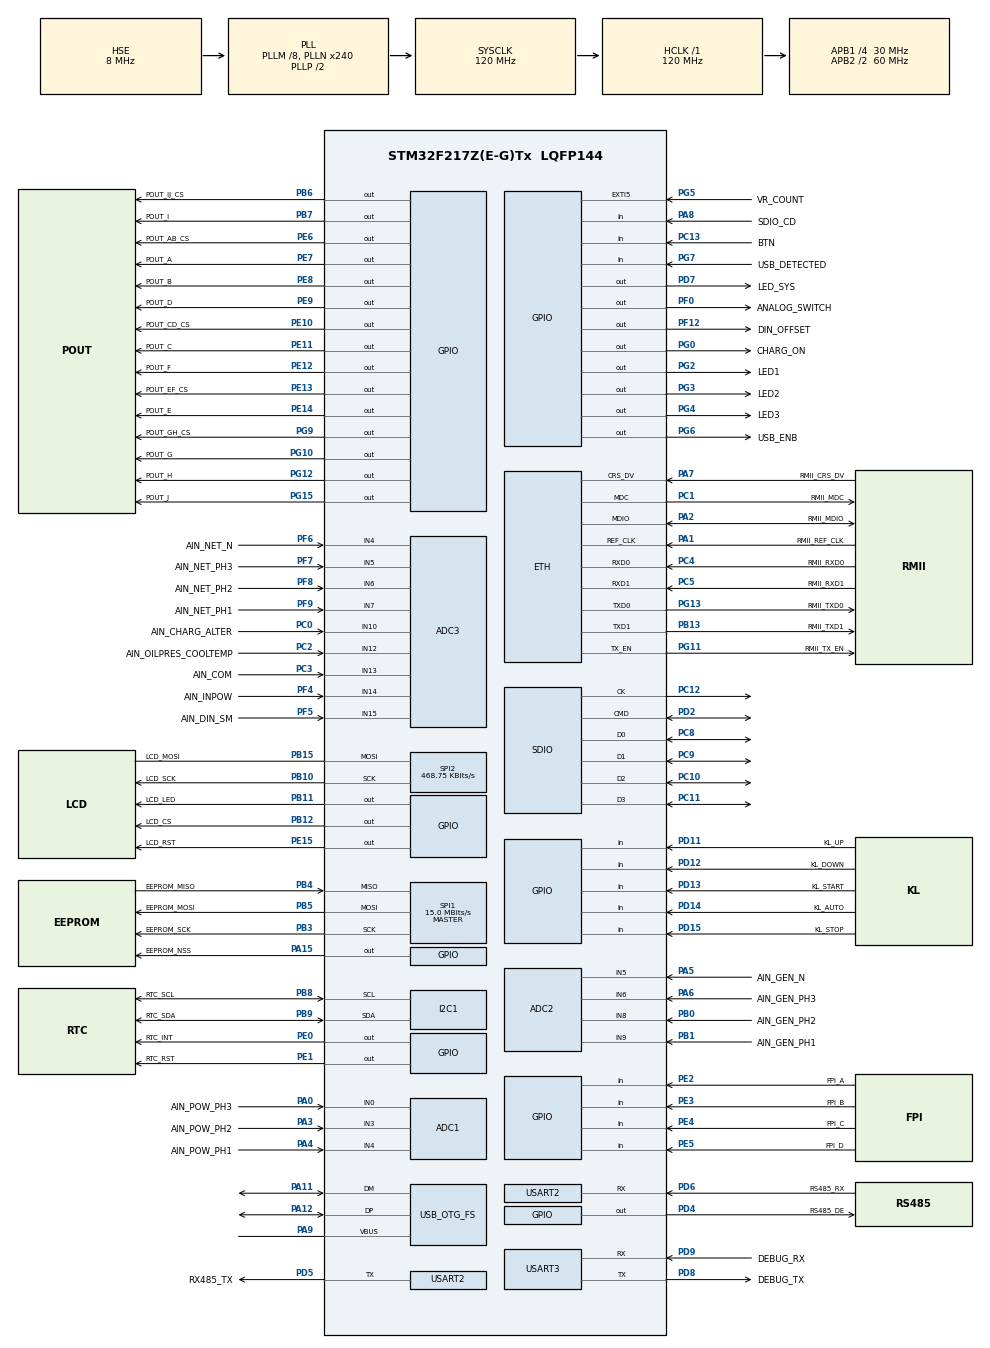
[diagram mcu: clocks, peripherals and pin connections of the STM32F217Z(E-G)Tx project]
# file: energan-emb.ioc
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ADC1.Channel-0\#ChannelRegularConversion=ADC_CHANNEL_0
ADC1.Channel-1\#ChannelRegularConversion=ADC_CHANNEL_3
ADC1.Channel-2\#ChannelRegularConversion=ADC_CHANNEL_4
ADC1.ClockPrescaler=ADC_CLOCK_SYNC_PCLK_DIV2
ADC1.DMAContinuousRequests=ENABLE
ADC1.ExternalTrigConv=ADC_EXTERNALTRIGCONV_T2_TRGO
ADC1.NbrOfConversion=3
ADC1.NbrOfConversionFlag=1
ADC1.Rank-0\#ChannelRegularConversion=1
ADC1.Rank-1\#ChannelRegularConversion=2
ADC1.Rank-2\#ChannelRegularConversion=3
ADC1.SamplingTime-0\#ChannelRegularConversion=ADC_SAMPLETIME_112CYCLES
ADC1.SamplingTime-1\#ChannelRegularConversion=ADC_SAMPLETIME_112CYCLES
ADC1.SamplingTime-2\#ChannelRegularConversion=ADC_SAMPLETIME_112CYCLES
ADC1.ScanConvMode=ENABLE
ADC1.master=1
ADC2.Channel-1\#ChannelRegularConversion=ADC_CHANNEL_6
ADC2.Channel-2\#ChannelRegularConversion=ADC_CHANNEL_8
ADC2.Channel-3\#ChannelRegularConversion=ADC_CHANNEL_9
ADC2.Channel-4\#ChannelRegularConversion=ADC_CHANNEL_5
ADC2.DMAContinuousRequests=ENABLE
ADC2.ExternalTrigConv=ADC_EXTERNALTRIGCONV_T8_TRGO
ADC2.NbrOfConversion=4
ADC2.NbrOfConversionFlag=1
ADC2.Rank-1\#ChannelRegularConversion=1
ADC2.Rank-2\#ChannelRegularConversion=2
ADC2.Rank-3\#ChannelRegularConversion=3
ADC2.Rank-4\#ChannelRegularConversion=4
ADC2.SamplingTime-1\#ChannelRegularConversion=ADC_SAMPLETIME_112CYCLES
ADC2.SamplingTime-2\#ChannelRegularConversion=ADC_SAMPLETIME_112CYCLES
ADC2.SamplingTime-3\#ChannelRegularConversion=ADC_SAMPLETIME_112CYCLES
ADC2.SamplingTime-4\#ChannelRegularConversion=ADC_SAMPLETIME_112CYCLES
ADC2.ScanConvMode=ENABLE
ADC3.Channel-0\#ChannelRegularConversion=ADC_CHANNEL_5
ADC3.Channel-10\#ChannelRegularConversion=ADC_CHANNEL_13
ADC3.Channel-11\#ChannelRegularConversion=ADC_CHANNEL_12
ADC3.Channel-12\#ChannelRegularConversion=ADC_CHANNEL_10
ADC3.Channel-5\#ChannelRegularConversion=ADC_CHANNEL_6
ADC3.Channel-6\#ChannelRegularConversion=ADC_CHANNEL_7
ADC3.Channel-7\#ChannelRegularConversion=ADC_CHANNEL_4
ADC3.Channel-8\#ChannelRegularConversion=ADC_CHANNEL_14
ADC3.Channel-9\#ChannelRegularConversion=ADC_CHANNEL_15
ADC3.DMAContinuousRequests=ENABLE
ADC3.ExternalTrigConv=ADC_EXTERNALTRIGCONV_T3_TRGO
ADC3.InjNumberOfConversion=0
ADC3.NbrOfConversion=9
ADC3.NbrOfConversionFlag=1
ADC3.Rank-0\#ChannelRegularConversion=1
ADC3.Rank-10\#ChannelRegularConversion=7
ADC3.Rank-11\#ChannelRegularConversion=8
ADC3.Rank-12\#ChannelRegularConversion=9
ADC3.Rank-5\#ChannelRegularConversion=2
ADC3.Rank-6\#ChannelRegularConversion=3
ADC3.Rank-7\#ChannelRegularConversion=4
ADC3.Rank-8\#ChannelRegularConversion=5
ADC3.Rank-9\#ChannelRegularConversion=6
ADC3.SamplingTime-0\#ChannelRegularConversion=ADC_SAMPLETIME_112CYCLES
ADC3.SamplingTime-10\#ChannelRegularConversion=ADC_SAMPLETIME_112CYCLES
ADC3.SamplingTime-11\#ChannelRegularConversion=ADC_SAMPLETIME_112CYCLES
ADC3.SamplingTime-12\#ChannelRegularConversion=ADC_SAMPLETIME_112CYCLES
ADC3.SamplingTime-5\#ChannelRegularConversion=ADC_SAMPLETIME_112CYCLES
ADC3.SamplingTime-6\#ChannelRegularConversion=ADC_SAMPLETIME_112CYCLES
ADC3.SamplingTime-7\#ChannelRegularConversion=ADC_SAMPLETIME_112CYCLES
ADC3.SamplingTime-8\#ChannelRegularConversion=ADC_SAMPLETIME_112CYCLES
ADC3.SamplingTime-9\#ChannelRegularConversion=ADC_SAMPLETIME_112CYCLES
ADC3.ScanConvMode=ENABLE
Dma.ADC1.2.Direction=DMA_PERIPH_TO_MEMORY
Dma.ADC1.2.FIFOMode=DMA_FIFOMODE_DISABLE
Dma.ADC1.2.Instance=DMA2_Stream0
Dma.ADC1.2.MemDataAlignment=DMA_MDATAALIGN_HALFWORD
Dma.ADC1.2.MemInc=DMA_MINC_ENABLE
Dma.ADC1.2.Mode=DMA_NORMAL
Dma.ADC1.2.PeriphDataAlignment=DMA_PDATAALIGN_HALFWORD
Dma.ADC1.2.PeriphInc=DMA_PINC_DISABLE
Dma.ADC1.2.Priority=DMA_PRIORITY_LOW
Dma.ADC2.1.Direction=DMA_PERIPH_TO_MEMORY
Dma.ADC2.1.FIFOMode=DMA_FIFOMODE_DISABLE
Dma.ADC2.1.Instance=DMA2_Stream2
Dma.ADC2.1.MemDataAlignment=DMA_MDATAALIGN_HALFWORD
Dma.ADC2.1.MemInc=DMA_MINC_ENABLE
Dma.ADC2.1.Mode=DMA_NORMAL
Dma.ADC2.1.PeriphDataAlignment=DMA_PDATAALIGN_HALFWORD
Dma.ADC2.1.PeriphInc=DMA_PINC_DISABLE
Dma.ADC2.1.Priority=DMA_PRIORITY_LOW
Dma.ADC3.0.Direction=DMA_PERIPH_TO_MEMORY
Dma.ADC3.0.FIFOMode=DMA_FIFOMODE_DISABLE
Dma.ADC3.0.Instance=DMA2_Stream1
Dma.ADC3.0.MemDataAlignment=DMA_MDATAALIGN_HALFWORD
Dma.ADC3.0.MemInc=DMA_MINC_ENABLE
Dma.ADC3.0.Mode=DMA_NORMAL
Dma.ADC3.0.PeriphDataAlignment=DMA_PDATAALIGN_HALFWORD
Dma.ADC3.0.PeriphInc=DMA_PINC_DISABLE
Dma.ADC3.0.Priority=DMA_PRIORITY_LOW
Dma.Request0=ADC3
Dma.Request1=ADC2
Dma.Request2=ADC1
Dma.Request3=SPI2_TX
Dma.Request4=SDIO_RX
Dma.Request5=SDIO_TX
Dma.SDIO_RX.4.Direction=DMA_PERIPH_TO_MEMORY
Dma.SDIO_RX.4.FIFOMode=DMA_FIFOMODE_ENABLE
Dma.SDIO_RX.4.FIFOThreshold=DMA_FIFO_THRESHOLD_FULL
Dma.SDIO_RX.4.Instance=DMA2_Stream3
Dma.SDIO_RX.4.MemBurst=DMA_MBURST_INC4
Dma.SDIO_RX.4.MemDataAlignment=DMA_MDATAALIGN_WORD
Dma.SDIO_RX.4.MemInc=DMA_MINC_ENABLE
Dma.SDIO_RX.4.Mode=DMA_PFCTRL
Dma.SDIO_RX.4.PeriphBurst=DMA_PBURST_INC4
Dma.SDIO_RX.4.PeriphDataAlignment=DMA_PDATAALIGN_WORD
Dma.SDIO_RX.4.PeriphInc=DMA_PINC_DISABLE
Dma.SDIO_RX.4.Priority=DMA_PRIORITY_LOW
Dma.SDIO_TX.5.Direction=DMA_MEMORY_TO_PERIPH
Dma.SDIO_TX.5.FIFOMode=DMA_FIFOMODE_ENABLE
Dma.SDIO_TX.5.FIFOThreshold=DMA_FIFO_THRESHOLD_FULL
Dma.SDIO_TX.5.Instance=DMA2_Stream6
Dma.SDIO_TX.5.MemBurst=DMA_MBURST_INC4
Dma.SDIO_TX.5.MemDataAlignment=DMA_MDATAALIGN_WORD
Dma.SDIO_TX.5.MemInc=DMA_MINC_ENABLE
Dma.SDIO_TX.5.Mode=DMA_PFCTRL
Dma.SDIO_TX.5.PeriphBurst=DMA_PBURST_INC4
Dma.SDIO_TX.5.PeriphDataAlignment=DMA_PDATAALIGN_WORD
Dma.SDIO_TX.5.PeriphInc=DMA_PINC_DISABLE
Dma.SDIO_TX.5.Priority=DMA_PRIORITY_LOW
Dma.SPI2_TX.3.Direction=DMA_MEMORY_TO_PERIPH
Dma.SPI2_TX.3.FIFOMode=DMA_FIFOMODE_DISABLE
Dma.SPI2_TX.3.Instance=DMA1_Stream4
Dma.SPI2_TX.3.MemDataAlignment=DMA_MDATAALIGN_BYTE
Dma.SPI2_TX.3.MemInc=DMA_MINC_ENABLE
Dma.SPI2_TX.3.Mode=DMA_NORMAL
Dma.SPI2_TX.3.PeriphDataAlignment=DMA_PDATAALIGN_BYTE
Dma.SPI2_TX.3.PeriphInc=DMA_PINC_DISABLE
Dma.SPI2_TX.3.Priority=DMA_PRIORITY_LOW
ETH.MACAddr=00\:10\:FA\:6E\:38\:4A
ETH.MediaInterface=ETH_MEDIA_INTERFACE_RMII
ETH.PHY_DUPLEX_STATUS=0x0010
ETH.PHY_SPEED_STATUS=0x0004
ETH.PHY_SR=0x1F
ETH.PhyAddress=0
FATFS.BSP.number=1
FATFS._CODE_PAGE=1
FATFS0.BSP.STBoard=false
FATFS0.BSP.api=Unknown
FATFS0.BSP.i2caddr=0
FATFS0.BSP.instance=PA8
FATFS0.BSP.ip=GPIO
FATFS0.BSP.mode=Input
FATFS0.BSP.name=Detect_SDIO
FATFS0.BSP.solution=PA8
FREERTOS.BinarySemaphores01=xLCDDelaySemph,Dynamic,NULL
FREERTOS.Tasks01=defaultTask,24,128,StartDefaultTask,Default,NULL,Dynamic,NULL,NULL;lcdTask,8,256,StartLcdTask,Default,NULL,Dynamic,NULL,NULL;usbTask,8,192,vStartUsbTask,As external,NULL,Dynamic,NULL,NULL;adcTask,24,403,StartADCTask,As external,NULL,Dynamic,NULL,NULL;keyboardTask,40,128,vKeyboardTask,As external,NULL,Dynamic,NULL,NULL;wdTask,32,128,vWDtask,Default,NULL,Dynamic,NULL,NULL
FREERTOS.configTIMER_TASK_PRIORITY=55
FREERTOS.configTOTAL_HEAP_SIZE=30720
IWDG.Prescaler=IWDG_PRESCALER_16
IWDG.Reload=3999
LWIP.CHECKSUM_BY_HARDWARE=0
LWIP.Version=v2.0.3_Cube
Mcu.Family=STM32F2
Mcu.Name=STM32F217Z(E-G)Tx
Mcu.Package=LQFP144
NVIC.DMA1_Stream4_IRQn=true\:5\:0\:false\:false\:true\:true\:false\:true\:true
NVIC.DMA2_Stream0_IRQn=true\:5\:0\:false\:false\:true\:true\:false\:true\:true
NVIC.DMA2_Stream1_IRQn=true\:5\:0\:false\:false\:true\:true\:false\:true\:true
NVIC.DMA2_Stream2_IRQn=true\:5\:0\:false\:false\:true\:true\:false\:true\:true
NVIC.DMA2_Stream3_IRQn=true\:5\:0\:false\:false\:true\:true\:false\:true\:true
NVIC.DMA2_Stream6_IRQn=true\:5\:0\:false\:false\:true\:true\:false\:true\:true
NVIC.ETH_IRQn=true\:5\:0\:false\:false\:true\:true\:false\:true\:true
NVIC.EXTI9_5_IRQn=true\:5\:0\:false\:false\:true\:true\:true\:true\:true
NVIC.OTG_FS_IRQn=true\:5\:0\:false\:false\:true\:true\:false\:true\:true
NVIC.PriorityGroup=NVIC_PRIORITYGROUP_4
NVIC.SDIO_IRQn=true\:5\:0\:false\:false\:true\:true\:true\:true\:true
NVIC.TIM2_IRQn=true\:5\:0\:false\:false\:true\:true\:true\:true\:true
NVIC.TIM3_IRQn=true\:5\:0\:false\:false\:true\:true\:true\:true\:true
NVIC.TIM4_IRQn=true\:0\:0\:false\:false\:true\:false\:false\:true\:true
NVIC.TIM5_IRQn=true\:5\:0\:false\:false\:true\:true\:true\:true\:true
NVIC.TIM6_DAC_IRQn=true\:5\:0\:false\:false\:true\:true\:true\:true\:true
NVIC.TIM7_IRQn=true\:5\:0\:false\:false\:true\:true\:true\:true\:true
NVIC.TIM8_BRK_TIM12_IRQn=true\:5\:0\:false\:false\:true\:true\:true\:true\:true
NVIC.TIM8_UP_TIM13_IRQn=true\:5\:0\:false\:false\:true\:true\:true\:true\:true
NVIC.TimeBase=TIM4_IRQn
NVIC.TimeBaseIP=TIM4
NVIC.USART2_IRQn=true\:5\:0\:false\:false\:true\:true\:true\:true\:true
NVIC.USART3_IRQn=true\:5\:0\:false\:false\:true\:true\:true\:true\:true
PA0-WKUP.GPIO_Label=AIN_POW_PH3
PA0-WKUP.Signal=ADCx_IN0
PA1.GPIO_Label=RMII_REF_CLK
PA1.Mode=RMII
PA1.Signal=ETH_REF_CLK
PA11.Mode=Device_Only
PA11.Signal=USB_OTG_FS_DM
PA12.Mode=Device_Only
PA12.Signal=USB_OTG_FS_DP
PA13.GPIO_Label=SWDIO
PA13.Mode=Serial_Wire
PA13.Signal=SYS_JTMS-SWDIO
PA14.GPIO_Label=SWCLK
PA14.Mode=Serial_Wire
PA14.Signal=SYS_JTCK-SWCLK
PA15.GPIO_Label=EEPROM_NSS
PA15.Signal=GPIO_Output
PA2.GPIO_Label=RMII_MDIO
PA2.Mode=RMII
PA2.Signal=ETH_MDIO
PA3.GPIO_Label=AIN_POW_PH2
PA3.Signal=ADCx_IN3
PA4.GPIO_Label=AIN_POW_PH1
PA4.Signal=ADCx_IN4
PA5.GPIO_Label=AIN_GEN_N
PA5.Signal=ADCx_IN5
PA6.GPIO_Label=AIN_GEN_PH3
PA6.Signal=ADCx_IN6
PA7.GPIO_Label=RMII_CRS_DV
PA7.Mode=RMII
PA7.Signal=ETH_CRS_DV
PA8.GPIO_Label=SDIO_CD
PA8.Signal=GPIO_Input
PA9.Mode=Activate_VBUS
PA9.Signal=USB_OTG_FS_VBUS
PB0.GPIO_Label=AIN_GEN_PH2
PB0.Signal=ADCx_IN8
PB1.GPIO_Label=AIN_GEN_PH1
PB1.Signal=ADCx_IN9
PB10.GPIO_Label=LCD_SCK
PB10.Mode=Simplex_Bidirectional_Master
PB10.Signal=SPI2_SCK
PB11.GPIO_Label=LCD_LED
PB11.Signal=GPIO_Output
PB12.GPIO_Label=LCD_CS
PB12.Signal=GPIO_Output
PB13.GPIO_Label=RMII_TXD1
PB13.Mode=RMII
PB13.Signal=ETH_TXD1
PB14.GPIO_Label=LCD_MISO
PB14.Signal=SPI2_MISO
PB15.GPIO_Label=LCD_MOSI
PB15.Mode=Simplex_Bidirectional_Master
PB15.Signal=SPI2_MOSI
PB3.GPIO_Label=EEPROM_SCK
PB3.Mode=Full_Duplex_Master
PB3.Signal=SPI1_SCK
PB4.GPIO_Label=EEPROM_MISO
PB4.Mode=Full_Duplex_Master
PB4.Signal=SPI1_MISO
PB5.GPIO_Label=EEPROM_MOSI
PB5.Mode=Full_Duplex_Master
PB5.Signal=SPI1_MOSI
PB6.GPIO_Label=POUT_IJ_CS
PB6.Signal=GPIO_Output
PB7.GPIO_Label=POUT_I
PB7.Signal=GPIO_Output
PB8.GPIO_Label=RTC_SCL
PB8.GPIO_Pu=GPIO_PULLUP
PB8.Mode=I2C
PB8.Signal=I2C1_SCL
PB9.GPIO_Label=RTC_SDA
PB9.GPIO_Pu=GPIO_PULLUP
PB9.Mode=I2C
PB9.Signal=I2C1_SDA
PC0.GPIO_Label=AIN_CHARG_ALTER
PC0.Signal=ADCx_IN10
PC1.GPIO_Label=RMII_MDC
PC1.Mode=RMII
PC1.Signal=ETH_MDC
PC10.Mode=SD_4_bits_Wide_bus
PC10.Signal=SDIO_D2
PC11.Mode=SD_4_bits_Wide_bus
PC11.Signal=SDIO_D3
PC12.Mode=SD_4_bits_Wide_bus
PC12.Signal=SDIO_CK
PC13.GPIO_Label=BTN
PC13.Signal=GPIO_Input
PC14-OSC32_IN.Signal=RCC_OSC32_IN
PC2.GPIO_Label=AIN_OILPRES_COOLTEMP
PC2.Signal=ADCx_IN12
PC3.GPIO_Label=AIN_COM
PC3.Signal=ADCx_IN13
PC4.GPIO_Label=RMII_RXD0
PC4.Mode=RMII
PC4.Signal=ETH_RXD0
PC5.GPIO_Label=RMII_RXD1
PC5.Mode=RMII
PC5.Signal=ETH_RXD1
PC8.Mode=SD_4_bits_Wide_bus
PC8.Signal=SDIO_D0
PC9.Mode=SD_4_bits_Wide_bus
PC9.Signal=SDIO_D1
PD0.Signal=CAN1_RX
PD1.Signal=CAN1_TX
PD11.GPIO_Label=KL_UP
PD11.Signal=GPIO_Input
PD12.GPIO_Label=KL_DOWN
PD12.Signal=GPIO_Input
PD13.GPIO_Label=KL_START
PD13.Signal=GPIO_Input
PD14.GPIO_Label=KL_AUTO
PD14.Signal=GPIO_Input
PD15.GPIO_Label=KL_STOP
PD15.Signal=GPIO_Input
PD2.Mode=SD_4_bits_Wide_bus
PD2.Signal=SDIO_CMD
PD4.GPIO_Label=RS485_DE
PD4.Signal=GPIO_Output
PD5.GPIO_Label=RX485_TX
PD5.Mode=Asynchronous
PD5.Signal=USART2_TX
PD6.GPIO_Label=RS485_RX
PD6.Mode=Asynchronous
PD6.Signal=USART2_RX
PD7.GPIO_Label=LED_SYS
PD7.PinState=GPIO_PIN_SET
PD7.Signal=GPIO_Output
PD8.GPIO_Label=DEBUG_TX
PD8.Mode=Asynchronous
PD8.Signal=USART3_TX
PD9.GPIO_Label=DEBUG_RX
PD9.Mode=Asynchronous
PD9.Signal=USART3_RX
PE0.GPIO_Label=RTC_INT
PE0.Signal=GPIO_Output
PE1.GPIO_Label=RTC_RST
PE1.Signal=GPIO_Output
PE10.GPIO_Label=POUT_CD_CS
PE10.Signal=GPIO_Output
PE11.GPIO_Label=POUT_C
PE11.Signal=GPIO_Output
PE12.GPIO_Label=POUT_F
PE12.Signal=GPIO_Output
PE13.GPIO_Label=POUT_EF_CS
PE13.Signal=GPIO_Output
PE14.GPIO_Label=POUT_E
PE14.Signal=GPIO_Output
PE15.GPIO_Label=LCD_RST
PE15.PinState=GPIO_PIN_SET
PE15.Signal=GPIO_Output
PE2.GPIO_Label=FPI_A
PE2.Signal=GPIO_Input
PE3.GPIO_Label=FPI_B
PE3.Signal=GPIO_Input
PE4.GPIO_Label=FPI_C
PE4.Signal=GPIO_Input
PE5.GPIO_Label=FPI_D
PE5.Signal=GPIO_Input
PE6.GPIO_Label=POUT_AB_CS
PE6.Signal=GPIO_Output
PE7.GPIO_Label=POUT_A
PE7.Signal=GPIO_Output
PE8.GPIO_Label=POUT_B
PE8.Signal=GPIO_Output
PE9.GPIO_Label=POUT_D
PE9.Signal=GPIO_Output
PF0.GPIO_Label=ANALOG_SWITCH
PF0.Signal=GPIO_Output
PF10.Signal=ADC3_IN8
PF12.GPIO_Label=DIN_OFFSET
PF12.Signal=GPIO_Output
PF4.GPIO_Label=AIN_INPOW
PF4.Mode=IN14
PF4.Signal=ADC3_IN14
PF5.GPIO_Label=AIN_DIN_SM
PF5.Mode=IN15
PF5.Signal=ADC3_IN15
PF6.GPIO_Label=AIN_NET_N
PF6.Mode=IN4
PF6.Signal=ADC3_IN4
PF7.GPIO_Label=AIN_NET_PH3
PF7.Mode=IN5
PF7.Signal=ADC3_IN5
PF8.GPIO_Label=AIN_NET_PH2
PF8.Mode=IN6
PF8.Signal=ADC3_IN6
PF9.GPIO_Label=AIN_NET_PH1
PF9.Mode=IN7
PF9.Signal=ADC3_IN7
PG0.GPIO_Label=CHARG_ON
PG0.Signal=GPIO_Output
PG10.GPIO_Label=POUT_G
PG10.Signal=GPIO_Output
PG11.GPIO_Label=RMII_TX_EN
PG11.Mode=RMII
PG11.Signal=ETH_TX_EN
PG12.GPIO_Label=POUT_H
PG12.Signal=GPIO_Output
PG13.GPIO_Label=RMII_TXD0
PG13.Mode=RMII
PG13.Signal=ETH_TXD0
PG15.GPIO_Label=POUT_J
PG15.Signal=GPIO_Output
PG2.GPIO_Label=LED1
PG2.PinState=GPIO_PIN_SET
PG2.Signal=GPIO_Output
PG3.GPIO_Label=LED2
PG3.PinState=GPIO_PIN_SET
PG3.Signal=GPIO_Output
PG4.GPIO_Label=LED3
PG4.PinState=GPIO_PIN_SET
PG4.Signal=GPIO_Output
PG5.GPIO_Label=VR_COUNT
PG5.Signal=GPXTI5
PG6.GPIO_Label=USB_ENB
PG6.Signal=GPIO_Output
PG7.GPIO_Label=USB_DETECTED
PG7.Signal=GPIO_Input
PG9.GPIO_Label=POUT_GH_CS
PG9.Signal=GPIO_Output
PH0-OSC_IN.Mode=HSE-External-Oscillator
PH0-OSC_IN.Signal=RCC_OSC_IN
PH1-OSC_OUT.Mode=HSE-External-Oscillator
PH1-OSC_OUT.Signal=RCC_OSC_OUT
ProjectManager.HeapSize=0x200
ProjectManager.StackSize=0x400
ProjectManager.TargetToolchain=STM32CubeIDE
RCC.48MHZClocksFreq_Value=48000000
RCC.AHBFreq_Value=120000000
RCC.APB1CLKDivider=RCC_HCLK_DIV4
RCC.APB1Freq_Value=30000000
RCC.APB1TimFreq_Value=60000000
RCC.APB2CLKDivider=RCC_HCLK_DIV2
RCC.APB2Freq_Value=60000000
RCC.APB2TimFreq_Value=120000000
RCC.CortexFreq_Value=120000000
RCC.HCLKFreq_Value=120000000
RCC.HSE_VALUE=8000000
RCC.HSI_VALUE=16000000
RCC.LSE_VALUE=32768
RCC.PLLM=8
RCC.PLLN=240
RCC.PLLQ=5
RCC.PLLSourceVirtual=RCC_PLLSOURCE_HSE
RCC.SYSCLKFreq_VALUE=120000000
RCC.SYSCLKSource=RCC_SYSCLKSOURCE_PLLCLK
RCC.VCOOutputFreq_Value=240000000
SDIO.ClockDiv=6
SH.ADCx_IN0.0=ADC1_IN0,IN0
SH.ADCx_IN10.0=ADC3_IN10,IN10
SH.ADCx_IN12.0=ADC3_IN12,IN12
SH.ADCx_IN13.0=ADC3_IN13,IN13
SH.ADCx_IN3.0=ADC1_IN3,IN3
SH.ADCx_IN4.0=ADC1_IN4,IN4
SH.ADCx_IN5.0=ADC2_IN5,IN5
SH.ADCx_IN6.0=ADC2_IN6,IN6
SH.ADCx_IN8.0=ADC2_IN8,IN8
SH.ADCx_IN9.0=ADC2_IN9,IN9
SPI1.BaudRatePrescaler=SPI_BAUDRATEPRESCALER_4
SPI1.CalculateBaudRate=15.0 MBits/s
SPI1.Direction=SPI_DIRECTION_2LINES
SPI1.Mode=SPI_MODE_MASTER
SPI1.VirtualType=VM_MASTER
SPI2.BaudRatePrescaler=SPI_BAUDRATEPRESCALER_64
SPI2.CLKPhase=SPI_PHASE_2EDGE
SPI2.CLKPolarity=SPI_POLARITY_HIGH
SPI2.CalculateBaudRate=468.75 KBits/s
SPI2.Direction=SPI_DIRECTION_1LINE
SPI2.Mode=SPI_MODE_MASTER
SPI2.VirtualType=VM_MASTER
TIM12.Period=201
TIM12.Prescaler=30001
TIM2.ClockDivision=TIM_CLOCKDIVISION_DIV4
TIM2.Period=1000
TIM2.TIM_MasterOutputTrigger=TIM_TRGO_UPDATE
TIM2.TIM_MasterSlaveMode=TIM_MASTERSLAVEMODE_DISABLE
TIM3.AutoReloadPreload=TIM_AUTORELOAD_PRELOAD_ENABLE
TIM3.ClockDivision=TIM_CLOCKDIVISION_DIV4
TIM3.Period=1000
TIM3.TIM_MasterOutputTrigger=TIM_TRGO_UPDATE
TIM5.Period=201
TIM5.Prescaler=30001
TIM6.Period=2001
TIM6.Prescaler=30001
TIM7.Period=72
TIM7.Prescaler=60
TIM8.AutoReloadPreload=TIM_AUTORELOAD_PRELOAD_ENABLE
TIM8.ClockDivision=TIM_CLOCKDIVISION_DIV4
TIM8.Period=1000
TIM8.TIM_MasterOutputTrigger=TIM_TRGO_UPDATE
TIM8.TIM_MasterSlaveMode=TIM_MASTERSLAVEMODE_DISABLE
USART2.VirtualMode=VM_ASYNC
USART3.VirtualMode=VM_ASYNC
USB_DEVICE.CLASS_NAME_FS=CUSTOM_HID
USB_DEVICE.CONFIGURATION_STRING_CUSTOMHID_FS=Energan
USB_DEVICE.INTERFACE_STRING_CUSTOMHID_FS=Energan IO Interface
USB_DEVICE.MANUFACTURER_STRING-CUSTOM_HID_FS=Energan
USB_DEVICE.PID_CUSTOMHID_FS=4285
USB_DEVICE.PRODUCT_STRING_CUSTOMHID_FS=Enrgan Diesel Generator Controller 
USB_DEVICE.USBD_CUSTOMHID_OUTREPORT_BUF_SIZE-CUSTOM_HID_FS=64
USB_DEVICE.USBD_CUSTOM_HID_REPORT_DESC_SIZE-CUSTOM_HID_FS=38
USB_DEVICE.VID-CUSTOM_HID_FS=5840
USB_DEVICE.VirtualMode-CUSTOM_HID_FS=CustomHid
USB_DEVICE.VirtualModeFS=Custom_Hid_FS
USB_OTG_FS.VirtualMode=Device_Only
VP_FATFS_VS_SDIO.Mode=SDIO
VP_FREERTOS_VS_CMSIS_V2.Mode=CMSIS_V2
VP_IWDG_VS_IWDG.Mode=IWDG_Activate
VP_LWIP_VS_Enabled.Mode=Enabled
VP_SYS_VS_tim4.Mode=TIM4
VP_TIM11_VS_ClockSourceINT.Mode=Enable_Timer
VP_TIM12_VS_ClockSourceINT.Mode=Internal
VP_TIM13_VS_ClockSourceINT.Mode=Enable_Timer
VP_TIM2_VS_ClockSourceINT.Mode=Internal
VP_TIM3_VS_ClockSourceINT.Mode=Internal
VP_TIM5_VS_ClockSourceINT.Mode=Internal
VP_TIM6_VS_ClockSourceINT.Mode=Enable_Timer
VP_TIM7_VS_ClockSourceINT.Mode=Enable_Timer
VP_TIM8_VS_ClockSourceINT.Mode=Internal
VP_USB_DEVICE_VS_USB_DEVICE_CUSTOM_HID_FS.Mode=CUSTOM_HID_FS
board=custom

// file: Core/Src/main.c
/* USER CODE BEGIN Header */
/**
  ******************************************************************************
  * @file           : main.c
  * @brief          : Main program body
  ******************************************************************************
  * @attention
  *
  * <h2><center>&copy; Copyright (c) 2021 STMicroelectronics.
  * All rights reserved.</center></h2>
  *
  * This software component is licensed by ST under BSD 3-Clause license,
  * the "License"; You may not use this file except in compliance with the
  * License. You may obtain a copy of the License at:
  *                        opensource.org/licenses/BSD-3-Clause
  *
  ******************************************************************************
  */
/* USER CODE END Header */
#include "main.h"
#include "cmsis_os.h"
#include "fatfs.h"
#include "lwip.h"
#include "usb_device.h"

/* USER CODE BEGIN Includes */
#include "task.h"
#include "EEPROM.h"
#include "RTC.h"
#include "common.h"
#include "chart.h"
#include "dataAPI.h"
#include "lcd.h"
#include "keyboard.h"
#include "menu.h"
#include "server.h"
#include "config.h"
#include "version.h"
#include "usbhid.h"
#include "storage.h"
#include "freeData.h"
#include "adc.h"
#include "fpi.h"
#include "fpo.h"
#include "vrSensor.h"
#include "engine.h"
#include "electro.h"
#include "controller.h"
#include "alarm.h"
#include "measurement.h"
#include "charger.h"
#include "mb.h"
#include "outputData.h"
#include "system.h"
#include "fatsd.h"

#include "dataSD.h"

#if defined ( UNIT_TEST )
  #include "unity.h"
  #include "tests.h"
#endif
/* USER CODE END Includes */

ADC_HandleTypeDef hadc1;
ADC_HandleTypeDef hadc2;
ADC_HandleTypeDef hadc3;
DMA_HandleTypeDef hdma_adc1;
DMA_HandleTypeDef hdma_adc2;
DMA_HandleTypeDef hdma_adc3;

I2C_HandleTypeDef hi2c1;

IWDG_HandleTypeDef hiwdg;

SD_HandleTypeDef hsd;
DMA_HandleTypeDef hdma_sdio_rx;
DMA_HandleTypeDef hdma_sdio_tx;

SPI_HandleTypeDef hspi1;
SPI_HandleTypeDef hspi2;
DMA_HandleTypeDef hdma_spi2_tx;

TIM_HandleTypeDef htim2;
TIM_HandleTypeDef htim3;
TIM_HandleTypeDef htim5;
TIM_HandleTypeDef htim6;
TIM_HandleTypeDef htim7;
TIM_HandleTypeDef htim8;
TIM_HandleTypeDef htim11;
TIM_HandleTypeDef htim12;
TIM_HandleTypeDef htim13;

UART_HandleTypeDef huart2;
UART_HandleTypeDef huart3;

/* Definitions for defaultTask */
osThreadId_t defaultTaskHandle;
const osThreadAttr_t defaultTask_attributes = {
  .name = "defaultTask",
  .stack_size = 128 * 4,
  .priority = (osPriority_t) osPriorityNormal,
};
/* Definitions for lcdTask */
osThreadId_t lcdTaskHandle;
const osThreadAttr_t lcdTask_attributes = {
  .name = "lcdTask",
  .stack_size = 256 * 4,
  .priority = (osPriority_t) osPriorityLow,
};
/* Definitions for usbTask */
osThreadId_t usbTaskHandle;
const osThreadAttr_t usbTask_attributes = {
  .name = "usbTask",
  .stack_size = 192 * 4,
  .priority = (osPriority_t) osPriorityLow,
};
/* Definitions for adcTask */
osThreadId_t adcTaskHandle;
const osThreadAttr_t adcTask_attributes = {
  .name = "adcTask",
  .stack_size = 403 * 4,
  .priority = (osPriority_t) osPriorityNormal,
};
/* Definitions for keyboardTask */
osThreadId_t keyboardTaskHandle;
const osThreadAttr_t keyboardTask_attributes = {
  .name = "keyboardTask",
  .stack_size = 128 * 4,
  .priority = (osPriority_t) osPriorityHigh,
};
/* Definitions for wdTask */
osThreadId_t wdTaskHandle;
const osThreadAttr_t wdTask_attributes = {
  .name = "wdTask",
  .stack_size = 128 * 4,
  .priority = (osPriority_t) osPriorityAboveNormal,
};
/* Definitions for xLCDDelaySemph */
osSemaphoreId_t xLCDDelaySemphHandle;
const osSemaphoreAttr_t xLCDDelaySemph_attributes = {
  .name = "xLCDDelaySemph"
};

void SystemClock_Config(void);
static void MX_GPIO_Init(void);
static void MX_DMA_Init(void);
static void MX_ADC3_Init(void);
static void MX_I2C1_Init(void);
static void MX_SPI1_Init(void);
static void MX_USART2_UART_Init(void);
static void MX_USART3_UART_Init(void);
static void MX_SPI2_Init(void);
static void MX_TIM2_Init(void);
static void MX_TIM3_Init(void);
static void MX_TIM5_Init(void);
static void MX_TIM6_Init(void);
static void MX_TIM7_Init(void);
static void MX_TIM11_Init(void);
static void MX_TIM12_Init(void);
static void MX_TIM13_Init(void);
static void MX_ADC2_Init(void);
static void MX_ADC1_Init(void);
static void MX_TIM8_Init(void);
static void MX_IWDG_Init(void);
static void MX_SDIO_SD_Init(void);
void StartDefaultTask(void *argument);
void StartLcdTask(void *argument);
extern void vStartUsbTask(void *argument);
extern void StartADCTask(void *argument);
extern void vKeyboardTask(void *argument);
void vWDtask(void *argument);

/* USER CODE BEGIN PFP */
/*
static const TaskHandle_t* notifyTrg[NOTIFY_TARGETS_NUMBER] =
{
  ( TaskHandle_t* )&lcdTaskHandle,
  ( TaskHandle_t* )&engineHandle,
  ( TaskHandle_t* )&fpiHandle,
  ( TaskHandle_t* )&controllerHandle,
  ( TaskHandle_t* )&electroHandle,
};
*/
static const FPI_INIT fpiInitStruct = {
  .pinA   = FPI_A_Pin,
  .pinB   = FPI_B_Pin,
  .pinC   = FPI_C_Pin,
  .pinD   = FPI_D_Pin,
  .pinCS  = DIN_OFFSET_Pin,
  .portA  = FPI_A_GPIO_Port,
  .portB  = FPI_B_GPIO_Port,
  .portC  = FPI_C_GPIO_Port,
  .portD  = FPI_D_GPIO_Port,
  .portCS = DIN_OFFSET_GPIO_Port
};
static const FPO_INIT fpoInitStruct = {
  .outPinA   = POUT_A_Pin,
  .outPinB   = POUT_B_Pin,
  .outPinC   = POUT_C_Pin,
  .outPinD   = POUT_D_Pin,
  .outPinE   = POUT_E_Pin,
  .outPinF   = POUT_F_Pin,
  .outPinG   = POUT_G_Pin,
  .outPinH   = POUT_H_Pin,
  .outPinI   = POUT_I_Pin,
  .outPinJ   = POUT_J_Pin,

  .outPortA  = POUT_A_GPIO_Port,
  .outPortB  = POUT_B_GPIO_Port,
  .outPortC  = POUT_C_GPIO_Port,
  .outPortD  = POUT_D_GPIO_Port,
  .outPortE  = POUT_E_GPIO_Port,
  .outPortF  = POUT_F_GPIO_Port,
  .outPortG  = POUT_G_GPIO_Port,
  .outPortH  = POUT_H_GPIO_Port,
  .outPortI  = POUT_I_GPIO_Port,
  .outPortJ  = POUT_J_GPIO_Port,

  .disPinAB  = POUT_AB_CS_Pin,
  .disPinCD  = POUT_CD_CS_Pin,
  .disPinEF  = POUT_EF_CS_Pin,
  .disPinGH  = POUT_GH_CS_Pin,
  .disPinIJ  = POUT_IJ_CS_Pin,
  .disPortAB = POUT_AB_CS_GPIO_Port,
  .disPortCD = POUT_CD_CS_GPIO_Port,
  .disPortEF = POUT_EF_CS_GPIO_Port,
  .disPortGH = POUT_GH_CS_GPIO_Port,
  .disPortIJ = POUT_IJ_CS_GPIO_Port,
};
static const CONTROLLER_INIT controllerInitStruct = {
  .autoPIN    = LED2_Pin,
  .autoGPIO   = LED2_GPIO_Port,
  .manualPIN  = 0U,
  .manualGPIO = NULL,
  .startPIN   = LED3_Pin,
  .startGPIO  = LED3_GPIO_Port,
  .loadPIN    = 0U,
  .loadGPIO   = NULL,
  .stopPIN    = LED1_Pin,
  .stopGPIO   = LED1_GPIO_Port,
};
static const MB_INIT_TYPE mbInit = {
  .uart = &huart2,
  .tim  = &htim13,
  .port = RS485_DE_GPIO_Port,
  .pin  = RS485_DE_Pin,
};
static const GPIO_TYPE chargGPIO = {
  .pin = CHARG_ON_Pin,
  .port = CHARG_ON_GPIO_Port,
};
static const EEPROM_TYPE storEE = {
  .SRWD      = M95Mxx_SRWD,
  .ID        = M95Mxx_ID,
  .protect   = M95Mxx_PROTECTION,
  .size      = M95M01_SIZE,
  .page      = M95Mxx_PAGE_SIZE,
  .frequensy = M95Mxx_CLOCK_FREQ,
  .timeout   = M95Mxx_TIMEOUT,
  .adrSize   = M95Mxx_ADR_SIZE,
  .spi       = &hspi1,
  .cs.pin    = EEPROM_NSS_Pin,
  .cs.port   = EEPROM_NSS_GPIO_Port
};
static const EEPROM_TYPE macEE = {
  .SRWD      = AA02E48_SRWD,
  .ID        = AA02E48_ID,
  .protect   = AA02E48_PROTECTION,
  .size      = AA02E48_SIZE,
  .page      = AA02E48_PAGE_SIZE,
  .frequensy = AA02E48_CLOCK_FREQ,
  .timeout   = AA02E48_TIMEOUT,
  .adrSize   = AA02E48_ADR_SIZE,
  .spi       = &hspi1,
  .cs.pin    = MAC_NSS_Pin,
  .cs.port   = MAC_NSS_GPIO_Port
};

/* USER CODE END PFP */

int main(void)
{

  /* MCU Configuration--------------------------------------------------------*/

  /* Reset of all peripherals, Initializes the Flash interface and the Systick. */

  HAL_Init();

  /* Configure the system clock */
  SystemClock_Config();

  /* Initialize all configured peripherals */
  MX_GPIO_Init();
  MX_DMA_Init();
  MX_ADC3_Init();
  MX_I2C1_Init();
  MX_SPI1_Init();
  MX_USART2_UART_Init();
  MX_USART3_UART_Init();
  MX_SPI2_Init();
  MX_TIM2_Init();
  MX_TIM3_Init();
  MX_TIM5_Init();
  MX_TIM6_Init();
  MX_TIM7_Init();
  MX_TIM11_Init();
  MX_TIM12_Init();
  MX_TIM13_Init();
  MX_ADC2_Init();
  MX_ADC1_Init();
  MX_TIM8_Init();
  MX_IWDG_Init();
  MX_SDIO_SD_Init();
  //MX_FATFS_Init();

  /* Init scheduler */
  osKernelInitialize();

  /* Create the semaphores(s) */
  /* creation of xLCDDelaySemph */
  xLCDDelaySemphHandle = osSemaphoreNew(1, 1, &xLCDDelaySemph_attributes);

  /* USER CODE BEGIN RTOS_SEMAPHORES */
  xLCDDelaySemphHandle = osSemaphoreNew(1, 1, &xLCDDelaySemph_attributes);
  /* USER CODE END RTOS_SEMAPHORES */

  /* Create the thread(s) */
  /* creation of defaultTask */
  defaultTaskHandle = osThreadNew(StartDefaultTask, NULL, &defaultTask_attributes);

  /* creation of lcdTask */
  lcdTaskHandle = osThreadNew(StartLcdTask, NULL, &lcdTask_attributes);

  /* creation of usbTask */
  usbTaskHandle = osThreadNew(vStartUsbTask, NULL, &usbTask_attributes);

  /* creation of adcTask */
  adcTaskHandle = osThreadNew(StartADCTask, NULL, &adcTask_attributes);

  /* creation of keyboardTask */
  keyboardTaskHandle = osThreadNew(vKeyboardTask, NULL, &keyboardTask_attributes);

  /* creation of wdTask */
  wdTaskHandle = osThreadNew(vWDtask, NULL, &wdTask_attributes);

  /* USER CODE BEGIN RTOS_EVENTS */
  vSetupKeyboard();
  vMenuMessageInit( adcTaskHandle );
  HAL_GPIO_WritePin( LCD_RST_GPIO_Port, LCD_RST_Pin, GPIO_PIN_SET );
  vLCDInit( xLCDDelaySemphHandle, &htim7, &hspi2 );
  vCHARTinitCharts();                               /* Charts data initialization */
  vRTCinit( &hi2c1 );                               /* RTC initialization         */
  vDATAAPIinit( &storEE );                          /* Data API initialization    */
  vUSBinit( usbTaskHandle );
  /* USER CODE END RTOS_EVENTS */

  /* Start scheduler */
  osKernelStart();

  /* We should never get here as control is now taken by the scheduler */
  /* Infinite loop */
  while (1)
  {

  }
}

void SystemClock_Config(void)
{
  RCC_OscInitTypeDef RCC_OscInitStruct = {0};
  RCC_ClkInitTypeDef RCC_ClkInitStruct = {0};

  /** Initializes the RCC Oscillators according to the specified parameters
  * in the RCC_OscInitTypeDef structure.
  */
  RCC_OscInitStruct.OscillatorType = RCC_OSCILLATORTYPE_LSI|RCC_OSCILLATORTYPE_HSE;
  RCC_OscInitStruct.HSEState = RCC_HSE_ON;
  RCC_OscInitStruct.LSIState = RCC_LSI_ON;
  RCC_OscInitStruct.PLL.PLLState = RCC_PLL_ON;
  RCC_OscInitStruct.PLL.PLLSource = RCC_PLLSOURCE_HSE;
  RCC_OscInitStruct.PLL.PLLM = 8;
  RCC_OscInitStruct.PLL.PLLN = 240;
  RCC_OscInitStruct.PLL.PLLP = RCC_PLLP_DIV2;
  RCC_OscInitStruct.PLL.PLLQ = 5;
  if (HAL_RCC_OscConfig(&RCC_OscInitStruct) != HAL_OK)
  {
    Error_Handler();
  }

  /** Initializes the CPU, AHB and APB buses clocks
  */
  RCC_ClkInitStruct.ClockType = RCC_CLOCKTYPE_HCLK|RCC_CLOCKTYPE_SYSCLK
                              |RCC_CLOCKTYPE_PCLK1|RCC_CLOCKTYPE_PCLK2;
  RCC_ClkInitStruct.SYSCLKSource = RCC_SYSCLKSOURCE_PLLCLK;
  RCC_ClkInitStruct.AHBCLKDivider = RCC_SYSCLK_DIV1;
  RCC_ClkInitStruct.APB1CLKDivider = RCC_HCLK_DIV4;
  RCC_ClkInitStruct.APB2CLKDivider = RCC_HCLK_DIV2;

  if (HAL_RCC_ClockConfig(&RCC_ClkInitStruct, FLASH_LATENCY_3) != HAL_OK)
  {
    Error_Handler();
  }
}

static void MX_ADC1_Init(void)
{

  ADC_ChannelConfTypeDef sConfig = {0};

  /** Configure the global features of the ADC (Clock, Resolution, Data Alignment and number of conversion)
  */
  hadc1.Instance = ADC1;
  hadc1.Init.ClockPrescaler = ADC_CLOCK_SYNC_PCLK_DIV2;
  hadc1.Init.Resolution = ADC_RESOLUTION_12B;
  hadc1.Init.ScanConvMode = ENABLE;
  hadc1.Init.ContinuousConvMode = DISABLE;
  hadc1.Init.DiscontinuousConvMode = DISABLE;
  hadc1.Init.ExternalTrigConvEdge = ADC_EXTERNALTRIGCONVEDGE_RISING;
  hadc1.Init.ExternalTrigConv = ADC_EXTERNALTRIGCONV_T2_TRGO;
  hadc1.Init.DataAlign = ADC_DATAALIGN_RIGHT;
  hadc1.Init.NbrOfConversion = 3;
  hadc1.Init.DMAContinuousRequests = ENABLE;
  hadc1.Init.EOCSelection = ADC_EOC_SINGLE_CONV;
  if (HAL_ADC_Init(&hadc1) != HAL_OK)
  {
    Error_Handler();
  }

  /** Configure for the selected ADC regular channel its corresponding rank in the sequencer and its sample time.
  */
  sConfig.Channel = ADC_CHANNEL_0;
  sConfig.Rank = 1;
  sConfig.SamplingTime = ADC_SAMPLETIME_112CYCLES;
  if (HAL_ADC_ConfigChannel(&hadc1, &sConfig) != HAL_OK)
  {
    Error_Handler();
  }

  /** Configure for the selected ADC regular channel its corresponding rank in the sequencer and its sample time.
  */
  sConfig.Channel = ADC_CHANNEL_3;
  sConfig.Rank = 2;
  if (HAL_ADC_ConfigChannel(&hadc1, &sConfig) != HAL_OK)
  {
    Error_Handler();
  }

  /** Configure for the selected ADC regular channel its corresponding rank in the sequencer and its sample time.
  */
  sConfig.Channel = ADC_CHANNEL_4;
  sConfig.Rank = 3;
  if (HAL_ADC_ConfigChannel(&hadc1, &sConfig) != HAL_OK)
  {
    Error_Handler();
  }
  /* USER CODE BEGIN ADC1_Init 2 */
  sConfig.Channel = ADC_CHANNEL_16;
  sConfig.Rank = 4;
  if (HAL_ADC_ConfigChannel(&hadc1, &sConfig) != HAL_OK)
  {
    Error_Handler();
  }
  /* USER CODE END ADC1_Init 2 */

}

static void MX_ADC2_Init(void)
{

  ADC_ChannelConfTypeDef sConfig = {0};

  /** Configure the global features of the ADC (Clock, Resolution, Data Alignment and number of conversion)
  */
  hadc2.Instance = ADC2;
  hadc2.Init.ClockPrescaler = ADC_CLOCK_SYNC_PCLK_DIV2;
  hadc2.Init.Resolution = ADC_RESOLUTION_12B;
  hadc2.Init.ScanConvMode = ENABLE;
  hadc2.Init.ContinuousConvMode = DISABLE;
  hadc2.Init.DiscontinuousConvMode = DISABLE;
  hadc2.Init.ExternalTrigConvEdge = ADC_EXTERNALTRIGCONVEDGE_RISING;
  hadc2.Init.ExternalTrigConv = ADC_EXTERNALTRIGCONV_T8_TRGO;
  hadc2.Init.DataAlign = ADC_DATAALIGN_RIGHT;
  hadc2.Init.NbrOfConversion = 4;
  hadc2.Init.DMAContinuousRequests = ENABLE;
  hadc2.Init.EOCSelection = ADC_EOC_SINGLE_CONV;
  if (HAL_ADC_Init(&hadc2) != HAL_OK)
  {
    Error_Handler();
  }

  /** Configure for the selected ADC regular channel its corresponding rank in the sequencer and its sample time.
  */
  sConfig.Channel = ADC_CHANNEL_6;
  sConfig.Rank = 1;
  sConfig.SamplingTime = ADC_SAMPLETIME_112CYCLES;
  if (HAL_ADC_ConfigChannel(&hadc2, &sConfig) != HAL_OK)
  {
    Error_Handler();
  }

  /** Configure for the selected ADC regular channel its corresponding rank in the sequencer and its sample time.
  */
  sConfig.Channel = ADC_CHANNEL_8;
  sConfig.Rank = 2;
  if (HAL_ADC_ConfigChannel(&hadc2, &sConfig) != HAL_OK)
  {
    Error_Handler();
  }

  /** Configure for the selected ADC regular channel its corresponding rank in the sequencer and its sample time.
  */
  sConfig.Channel = ADC_CHANNEL_9;
  sConfig.Rank = 3;
  if (HAL_ADC_ConfigChannel(&hadc2, &sConfig) != HAL_OK)
  {
    Error_Handler();
  }

  /** Configure for the selected ADC regular channel its corresponding rank in the sequencer and its sample time.
  */
  sConfig.Channel = ADC_CHANNEL_5;
  sConfig.Rank = 4;
  if (HAL_ADC_ConfigChannel(&hadc2, &sConfig) != HAL_OK)
  {
    Error_Handler();
  }

}

static void MX_ADC3_Init(void)
{

  ADC_ChannelConfTypeDef sConfig = {0};

  /** Configure the global features of the ADC (Clock, Resolution, Data Alignment and number of conversion)
  */
  hadc3.Instance = ADC3;
  hadc3.Init.ClockPrescaler = ADC_CLOCK_SYNC_PCLK_DIV2;
  hadc3.Init.Resolution = ADC_RESOLUTION_12B;
  hadc3.Init.ScanConvMode = ENABLE;
  hadc3.Init.ContinuousConvMode = DISABLE;
  hadc3.Init.DiscontinuousConvMode = DISABLE;
  hadc3.Init.ExternalTrigConvEdge = ADC_EXTERNALTRIGCONVEDGE_RISING;
  hadc3.Init.ExternalTrigConv = ADC_EXTERNALTRIGCONV_T3_TRGO;
  hadc3.Init.DataAlign = ADC_DATAALIGN_RIGHT;
  hadc3.Init.NbrOfConversion = 9;
  hadc3.Init.DMAContinuousRequests = ENABLE;
  hadc3.Init.EOCSelection = ADC_EOC_SINGLE_CONV;
  if (HAL_ADC_Init(&hadc3) != HAL_OK)
  {
    Error_Handler();
  }

  /** Configure for the selected ADC regular channel its corresponding rank in the sequencer and its sample time.
  */
  sConfig.Channel = ADC_CHANNEL_5;
  sConfig.Rank = 1;
  sConfig.SamplingTime = ADC_SAMPLETIME_112CYCLES;
  if (HAL_ADC_ConfigChannel(&hadc3, &sConfig) != HAL_OK)
  {
    Error_Handler();
  }

  /** Configure for the selected ADC regular channel its corresponding rank in the sequencer and its sample time.
  */
  sConfig.Channel = ADC_CHANNEL_6;
  sConfig.Rank = 2;
  if (HAL_ADC_ConfigChannel(&hadc3, &sConfig) != HAL_OK)
  {
    Error_Handler();
  }

  /** Configure for the selected ADC regular channel its corresponding rank in the sequencer and its sample time.
  */
  sConfig.Channel = ADC_CHANNEL_7;
  sConfig.Rank = 3;
  if (HAL_ADC_ConfigChannel(&hadc3, &sConfig) != HAL_OK)
  {
    Error_Handler();
  }

  /** Configure for the selected ADC regular channel its corresponding rank in the sequencer and its sample time.
  */
  sConfig.Channel = ADC_CHANNEL_4;
  sConfig.Rank = 4;
  if (HAL_ADC_ConfigChannel(&hadc3, &sConfig) != HAL_OK)
  {
    Error_Handler();
  }

  /** Configure for the selected ADC regular channel its corresponding rank in the sequencer and its sample time.
  */
  sConfig.Channel = ADC_CHANNEL_14;
  sConfig.Rank = 5;
  if (HAL_ADC_ConfigChannel(&hadc3, &sConfig) != HAL_OK)
  {
    Error_Handler();
  }

  /** Configure for the selected ADC regular channel its corresponding rank in the sequencer and its sample time.
  */
  sConfig.Channel = ADC_CHANNEL_15;
  sConfig.Rank = 6;
  if (HAL_ADC_ConfigChannel(&hadc3, &sConfig) != HAL_OK)
  {
    Error_Handler();
  }

  /** Configure for the selected ADC regular channel its corresponding rank in the sequencer and its sample time.
  */
  sConfig.Channel = ADC_CHANNEL_13;
  sConfig.Rank = 7;
  if (HAL_ADC_ConfigChannel(&hadc3, &sConfig) != HAL_OK)
  {
    Error_Handler();
  }

  /** Configure for the selected ADC regular channel its corresponding rank in the sequencer and its sample time.
  */
  sConfig.Channel = ADC_CHANNEL_12;
  sConfig.Rank = 8;
  if (HAL_ADC_ConfigChannel(&hadc3, &sConfig) != HAL_OK)
  {
    Error_Handler();
  }

  /** Configure for the selected ADC regular channel its corresponding rank in the sequencer and its sample time.
  */
  sConfig.Channel = ADC_CHANNEL_10;
  sConfig.Rank = 9;
  if (HAL_ADC_ConfigChannel(&hadc3, &sConfig) != HAL_OK)
  {
    Error_Handler();
  }

}

static void MX_I2C1_Init(void)
{

  hi2c1.Instance = I2C1;
  hi2c1.Init.ClockSpeed = 100000;
  hi2c1.Init.DutyCycle = I2C_DUTYCYCLE_2;
  hi2c1.Init.OwnAddress1 = 0;
  hi2c1.Init.AddressingMode = I2C_ADDRESSINGMODE_7BIT;
  hi2c1.Init.DualAddressMode = I2C_DUALADDRESS_DISABLE;
  hi2c1.Init.OwnAddress2 = 0;
  hi2c1.Init.GeneralCallMode = I2C_GENERALCALL_DISABLE;
  hi2c1.Init.NoStretchMode = I2C_NOSTRETCH_DISABLE;
  if (HAL_I2C_Init(&hi2c1) != HAL_OK)
  {
    Error_Handler();
  }

}

static void MX_IWDG_Init(void)
{

  /* USER CODE BEGIN IWDG_Init 0 */
  #ifdef DEBUG
    __HAL_DBGMCU_FREEZE_IWDG();
  #endif
  /* USER CODE END IWDG_Init 0 */

  hiwdg.Instance = IWDG;
  hiwdg.Init.Prescaler = IWDG_PRESCALER_16;
  hiwdg.Init.Reload = 3999;
  if (HAL_IWDG_Init(&hiwdg) != HAL_OK)
  {
    Error_Handler();
  }

}

static void MX_SDIO_SD_Init(void)
{

  hsd.Instance = SDIO;
  hsd.Init.ClockEdge = SDIO_CLOCK_EDGE_RISING;
  hsd.Init.ClockBypass = SDIO_CLOCK_BYPASS_DISABLE;
  hsd.Init.ClockPowerSave = SDIO_CLOCK_POWER_SAVE_DISABLE;
  hsd.Init.BusWide = SDIO_BUS_WIDE_1B;
  hsd.Init.HardwareFlowControl = SDIO_HARDWARE_FLOW_CONTROL_DISABLE;
  hsd.Init.ClockDiv = 6;

}

static void MX_SPI1_Init(void)
{

  /* SPI1 parameter configuration*/
  hspi1.Instance = SPI1;
  hspi1.Init.Mode = SPI_MODE_MASTER;
  hspi1.Init.Direction = SPI_DIRECTION_2LINES;
  hspi1.Init.DataSize = SPI_DATASIZE_8BIT;
  hspi1.Init.CLKPolarity = SPI_POLARITY_LOW;
  hspi1.Init.CLKPhase = SPI_PHASE_1EDGE;
  hspi1.Init.NSS = SPI_NSS_SOFT;
  hspi1.Init.BaudRatePrescaler = SPI_BAUDRATEPRESCALER_4;
  hspi1.Init.FirstBit = SPI_FIRSTBIT_MSB;
  hspi1.Init.TIMode = SPI_TIMODE_DISABLE;
  hspi1.Init.CRCCalculation = SPI_CRCCALCULATION_DISABLE;
  hspi1.Init.CRCPolynomial = 10;
  if (HAL_SPI_Init(&hspi1) != HAL_OK)
  {
    Error_Handler();
  }

}

static void MX_SPI2_Init(void)
{

  /* USER CODE BEGIN SPI2_Init 1 */
   GPIO_InitTypeDef GPIO_InitStruct = {0};
   GPIO_InitStruct.Pin = LCD_MISO_Pin;
   GPIO_InitStruct.Mode = GPIO_MODE_OUTPUT_PP;
   GPIO_InitStruct.Pull =  GPIO_PULLUP;
   GPIO_InitStruct.Speed = GPIO_SPEED_FREQ_LOW;
   HAL_GPIO_Init(LCD_MISO_GPIO_Port, &GPIO_InitStruct);

  /* USER CODE END SPI2_Init 1 */
  /* SPI2 parameter configuration*/
  hspi2.Instance = SPI2;
  hspi2.Init.Mode = SPI_MODE_MASTER;
  hspi2.Init.Direction = SPI_DIRECTION_1LINE;
  hspi2.Init.DataSize = SPI_DATASIZE_8BIT;
  hspi2.Init.CLKPolarity = SPI_POLARITY_HIGH;
  hspi2.Init.CLKPhase = SPI_PHASE_2EDGE;
  hspi2.Init.NSS = SPI_NSS_SOFT;
  hspi2.Init.BaudRatePrescaler = SPI_BAUDRATEPRESCALER_64;
  hspi2.Init.FirstBit = SPI_FIRSTBIT_MSB;
  hspi2.Init.TIMode = SPI_TIMODE_DISABLE;
  hspi2.Init.CRCCalculation = SPI_CRCCALCULATION_DISABLE;
  hspi2.Init.CRCPolynomial = 10;
  if (HAL_SPI_Init(&hspi2) != HAL_OK)
  {
    Error_Handler();
  }

}

static void MX_TIM2_Init(void)
{

  TIM_ClockConfigTypeDef sClockSourceConfig = {0};
  TIM_MasterConfigTypeDef sMasterConfig = {0};

  htim2.Instance = TIM2;
  htim2.Init.Prescaler = 0;
  htim2.Init.CounterMode = TIM_COUNTERMODE_UP;
  htim2.Init.Period = 1000;
  htim2.Init.ClockDivision = TIM_CLOCKDIVISION_DIV4;
  htim2.Init.AutoReloadPreload = TIM_AUTORELOAD_PRELOAD_DISABLE;
  if (HAL_TIM_Base_Init(&htim2) != HAL_OK)
  {
    Error_Handler();
  }
  sClockSourceConfig.ClockSource = TIM_CLOCKSOURCE_INTERNAL;
  if (HAL_TIM_ConfigClockSource(&htim2, &sClockSourceConfig) != HAL_OK)
  {
    Error_Handler();
  }
  sMasterConfig.MasterOutputTrigger = TIM_TRGO_UPDATE;
  sMasterConfig.MasterSlaveMode = TIM_MASTERSLAVEMODE_DISABLE;
  if (HAL_TIMEx_MasterConfigSynchronization(&htim2, &sMasterConfig) != HAL_OK)
  {
    Error_Handler();
  }

}

static void MX_TIM3_Init(void)
{

  TIM_ClockConfigTypeDef sClockSourceConfig = {0};
  TIM_MasterConfigTypeDef sMasterConfig = {0};

  htim3.Instance = TIM3;
  htim3.Init.Prescaler = 0;
  htim3.Init.CounterMode = TIM_COUNTERMODE_UP;
  htim3.Init.Period = 1000;
  htim3.Init.ClockDivision = TIM_CLOCKDIVISION_DIV4;
  htim3.Init.AutoReloadPreload = TIM_AUTORELOAD_PRELOAD_ENABLE;
  if (HAL_TIM_Base_Init(&htim3) != HAL_OK)
  {
    Error_Handler();
  }
  sClockSourceConfig.ClockSource = TIM_CLOCKSOURCE_INTERNAL;
  if (HAL_TIM_ConfigClockSource(&htim3, &sClockSourceConfig) != HAL_OK)
  {
    Error_Handler();
  }
  sMasterConfig.MasterOutputTrigger = TIM_TRGO_UPDATE;
  sMasterConfig.MasterSlaveMode = TIM_MASTERSLAVEMODE_DISABLE;
  if (HAL_TIMEx_MasterConfigSynchronization(&htim3, &sMasterConfig) != HAL_OK)
  {
    Error_Handler();
  }

}

static void MX_TIM5_Init(void)
{

  TIM_ClockConfigTypeDef sClockSourceConfig = {0};
  TIM_MasterConfigTypeDef sMasterConfig = {0};

  htim5.Instance = TIM5;
  htim5.Init.Prescaler = 30001;
  htim5.Init.CounterMode = TIM_COUNTERMODE_UP;
  htim5.Init.Period = 201;
  htim5.Init.ClockDivision = TIM_CLOCKDIVISION_DIV1;
  htim5.Init.AutoReloadPreload = TIM_AUTORELOAD_PRELOAD_DISABLE;
  if (HAL_TIM_Base_Init(&htim5) != HAL_OK)
  {
    Error_Handler();
  }
  sClockSourceConfig.ClockSource = TIM_CLOCKSOURCE_INTERNAL;
  if (HAL_TIM_ConfigClockSource(&htim5, &sClockSourceConfig) != HAL_OK)
  {
    Error_Handler();
  }
  sMasterConfig.MasterOutputTrigger = TIM_TRGO_RESET;
  sMasterConfig.MasterSlaveMode = TIM_MASTERSLAVEMODE_DISABLE;
  if (HAL_TIMEx_MasterConfigSynchronization(&htim5, &sMasterConfig) != HAL_OK)
  {
    Error_Handler();
  }

}

static void MX_TIM6_Init(void)
{

  TIM_MasterConfigTypeDef sMasterConfig = {0};

  htim6.Instance = TIM6;
  htim6.Init.Prescaler = 30001;
  htim6.Init.CounterMode = TIM_COUNTERMODE_UP;
  htim6.Init.Period = 2001;
  htim6.Init.AutoReloadPreload = TIM_AUTORELOAD_PRELOAD_DISABLE;
  if (HAL_TIM_Base_Init(&htim6) != HAL_OK)
  {
    Error_Handler();
  }
  sMasterConfig.MasterOutputTrigger = TIM_TRGO_RESET;
  sMasterConfig.MasterSlaveMode = TIM_MASTERSLAVEMODE_DISABLE;
  if (HAL_TIMEx_MasterConfigSynchronization(&htim6, &sMasterConfig) != HAL_OK)
  {
    Error_Handler();
  }

}

static void MX_TIM7_Init(void)
{

  TIM_MasterConfigTypeDef sMasterConfig = {0};

  htim7.Instance = TIM7;
  htim7.Init.Prescaler = 60;
  htim7.Init.CounterMode = TIM_COUNTERMODE_UP;
  htim7.Init.Period = 72;
  htim7.Init.AutoReloadPreload = TIM_AUTORELOAD_PRELOAD_DISABLE;
  if (HAL_TIM_Base_Init(&htim7) != HAL_OK)
  {
    Error_Handler();
  }
  sMasterConfig.MasterOutputTrigger = TIM_TRGO_RESET;
  sMasterConfig.MasterSlaveMode = TIM_MASTERSLAVEMODE_DISABLE;
  if (HAL_TIMEx_MasterConfigSynchronization(&htim7, &sMasterConfig) != HAL_OK)
  {
    Error_Handler();
  }

}

static void MX_TIM8_Init(void)
{

  TIM_ClockConfigTypeDef sClockSourceConfig = {0};
  TIM_MasterConfigTypeDef sMasterConfig = {0};

  htim8.Instance = TIM8;
  htim8.Init.Prescaler = 0;
  htim8.Init.CounterMode = TIM_COUNTERMODE_UP;
  htim8.Init.Period = 1000;
  htim8.Init.ClockDivision = TIM_CLOCKDIVISION_DIV4;
  htim8.Init.RepetitionCounter = 0;
  htim8.Init.AutoReloadPreload = TIM_AUTORELOAD_PRELOAD_ENABLE;
  if (HAL_TIM_Base_Init(&htim8) != HAL_OK)
  {
    Error_Handler();
  }
  sClockSourceConfig.ClockSource = TIM_CLOCKSOURCE_INTERNAL;
  if (HAL_TIM_ConfigClockSource(&htim8, &sClockSourceConfig) != HAL_OK)
  {
    Error_Handler();
  }
  sMasterConfig.MasterOutputTrigger = TIM_TRGO_UPDATE;
  sMasterConfig.MasterSlaveMode = TIM_MASTERSLAVEMODE_DISABLE;
  if (HAL_TIMEx_MasterConfigSynchronization(&htim8, &sMasterConfig) != HAL_OK)
  {
    Error_Handler();
  }

}

static void MX_TIM11_Init(void)
{

  htim11.Instance = TIM11;
  htim11.Init.Prescaler = 0;
  htim11.Init.CounterMode = TIM_COUNTERMODE_UP;
  htim11.Init.Period = 65535;
  htim11.Init.ClockDivision = TIM_CLOCKDIVISION_DIV1;
  htim11.Init.AutoReloadPreload = TIM_AUTORELOAD_PRELOAD_DISABLE;
  if (HAL_TIM_Base_Init(&htim11) != HAL_OK)
  {
    Error_Handler();
  }

}

static void MX_TIM12_Init(void)
{

  TIM_ClockConfigTypeDef sClockSourceConfig = {0};

  htim12.Instance = TIM12;
  htim12.Init.Prescaler = 30001;
  htim12.Init.CounterMode = TIM_COUNTERMODE_UP;
  htim12.Init.Period = 201;
  htim12.Init.ClockDivision = TIM_CLOCKDIVISION_DIV1;
  htim12.Init.AutoReloadPreload = TIM_AUTORELOAD_PRELOAD_DISABLE;
  if (HAL_TIM_Base_Init(&htim12) != HAL_OK)
  {
    Error_Handler();
  }
  sClockSourceConfig.ClockSource = TIM_CLOCKSOURCE_INTERNAL;
  if (HAL_TIM_ConfigClockSource(&htim12, &sClockSourceConfig) != HAL_OK)
  {
    Error_Handler();
  }

}

static void MX_TIM13_Init(void)
{

  htim13.Instance = TIM13;
  htim13.Init.Prescaler = 0;
  htim13.Init.CounterMode = TIM_COUNTERMODE_UP;
  htim13.Init.Period = 65535;
  htim13.Init.ClockDivision = TIM_CLOCKDIVISION_DIV1;
  htim13.Init.AutoReloadPreload = TIM_AUTORELOAD_PRELOAD_DISABLE;
  if (HAL_TIM_Base_Init(&htim13) != HAL_OK)
  {
    Error_Handler();
  }

}

static void MX_USART2_UART_Init(void)
{

  huart2.Instance = USART2;
  huart2.Init.BaudRate = 115200;
  huart2.Init.WordLength = UART_WORDLENGTH_8B;
  huart2.Init.StopBits = UART_STOPBITS_1;
  huart2.Init.Parity = UART_PARITY_NONE;
  huart2.Init.Mode = UART_MODE_TX_RX;
  huart2.Init.HwFlowCtl = UART_HWCONTROL_NONE;
  huart2.Init.OverSampling = UART_OVERSAMPLING_16;
  if (HAL_UART_Init(&huart2) != HAL_OK)
  {
    Error_Handler();
  }

}

static void MX_USART3_UART_Init(void)
{

  huart3.Instance = USART3;
  huart3.Init.BaudRate = 115200;
  huart3.Init.WordLength = UART_WORDLENGTH_8B;
  huart3.Init.StopBits = UART_STOPBITS_1;
  huart3.Init.Parity = UART_PARITY_NONE;
  huart3.Init.Mode = UART_MODE_TX_RX;
  huart3.Init.HwFlowCtl = UART_HWCONTROL_NONE;
  huart3.Init.OverSampling = UART_OVERSAMPLING_16;
  if (HAL_UART_Init(&huart3) != HAL_OK)
  {
    Error_Handler();
  }

}

static void MX_DMA_Init(void)
{

  /* DMA controller clock enable */
  __HAL_RCC_DMA2_CLK_ENABLE();
  __HAL_RCC_DMA1_CLK_ENABLE();

  /* DMA interrupt init */
  /* DMA1_Stream4_IRQn interrupt configuration */
  HAL_NVIC_SetPriority(DMA1_Stream4_IRQn, 5, 0);
  HAL_NVIC_EnableIRQ(DMA1_Stream4_IRQn);
  /* DMA2_Stream0_IRQn interrupt configuration */
  HAL_NVIC_SetPriority(DMA2_Stream0_IRQn, 5, 0);
  HAL_NVIC_EnableIRQ(DMA2_Stream0_IRQn);
  /* DMA2_Stream1_IRQn interrupt configuration */
  HAL_NVIC_SetPriority(DMA2_Stream1_IRQn, 5, 0);
  HAL_NVIC_EnableIRQ(DMA2_Stream1_IRQn);
  /* DMA2_Stream2_IRQn interrupt configuration */
  HAL_NVIC_SetPriority(DMA2_Stream2_IRQn, 5, 0);
  HAL_NVIC_EnableIRQ(DMA2_Stream2_IRQn);
  /* DMA2_Stream3_IRQn interrupt configuration */
  HAL_NVIC_SetPriority(DMA2_Stream3_IRQn, 5, 0);
  HAL_NVIC_EnableIRQ(DMA2_Stream3_IRQn);
  /* DMA2_Stream6_IRQn interrupt configuration */
  HAL_NVIC_SetPriority(DMA2_Stream6_IRQn, 5, 0);
  HAL_NVIC_EnableIRQ(DMA2_Stream6_IRQn);

}

static void MX_GPIO_Init(void)
{
  GPIO_InitTypeDef GPIO_InitStruct = {0};

  /* GPIO Ports Clock Enable */
  __HAL_RCC_GPIOE_CLK_ENABLE();
  __HAL_RCC_GPIOC_CLK_ENABLE();
  __HAL_RCC_GPIOF_CLK_ENABLE();
  __HAL_RCC_GPIOH_CLK_ENABLE();
  __HAL_RCC_GPIOA_CLK_ENABLE();
  __HAL_RCC_GPIOB_CLK_ENABLE();
  __HAL_RCC_GPIOG_CLK_ENABLE();
  __HAL_RCC_GPIOD_CLK_ENABLE();

  /*Configure GPIO pin Output Level */
  HAL_GPIO_WritePin(GPIOE, POUT_AB_CS_Pin|POUT_A_Pin|POUT_B_Pin|POUT_D_Pin
                          |POUT_CD_CS_Pin|POUT_C_Pin|POUT_F_Pin|POUT_EF_CS_Pin
                          |POUT_E_Pin|RTC_INT_Pin|RTC_RST_Pin, GPIO_PIN_RESET);

  /*Configure GPIO pin Output Level */
  HAL_GPIO_WritePin(GPIOF, ANALOG_SWITCH_Pin|DIN_OFFSET_Pin, GPIO_PIN_RESET);

  /*Configure GPIO pin Output Level */
  HAL_GPIO_WritePin(GPIOG, CHARG_ON_Pin|USB_ENB_Pin|POUT_GH_CS_Pin|POUT_G_Pin
                          |POUT_H_Pin|POUT_J_Pin, GPIO_PIN_RESET);

  /*Configure GPIO pin Output Level */
  HAL_GPIO_WritePin(LCD_RST_GPIO_Port, LCD_RST_Pin, GPIO_PIN_SET);

  /*Configure GPIO pin Output Level */
  HAL_GPIO_WritePin(GPIOB, LCD_LED_Pin|LCD_CS_Pin|POUT_IJ_CS_Pin|POUT_I_Pin, GPIO_PIN_RESET);

  /*Configure GPIO pin Output Level */
  HAL_GPIO_WritePin(GPIOG, LED1_Pin|LED2_Pin|LED3_Pin, GPIO_PIN_SET);

  /*Configure GPIO pin Output Level */
  HAL_GPIO_WritePin(EEPROM_NSS_GPIO_Port, EEPROM_NSS_Pin, GPIO_PIN_RESET);
  HAL_GPIO_WritePin(MAC_NSS_GPIO_Port, MAC_NSS_Pin, GPIO_PIN_RESET);

  /*Configure GPIO pin Output Level */
  HAL_GPIO_WritePin(RS485_DE_GPIO_Port, RS485_DE_Pin, GPIO_PIN_RESET);

  /*Configure GPIO pin Output Level */
  HAL_GPIO_WritePin(LED_SYS_GPIO_Port, LED_SYS_Pin, GPIO_PIN_SET);

  /*Configure GPIO pins : FPI_A_Pin FPI_B_Pin FPI_C_Pin FPI_D_Pin */
  GPIO_InitStruct.Pin = FPI_A_Pin|FPI_B_Pin|FPI_C_Pin|FPI_D_Pin;
  GPIO_InitStruct.Mode = GPIO_MODE_INPUT;
  GPIO_InitStruct.Pull = GPIO_NOPULL;
  HAL_GPIO_Init(GPIOE, &GPIO_InitStruct);

  /*Configure GPIO pins : POUT_AB_CS_Pin POUT_A_Pin POUT_B_Pin POUT_D_Pin
                           POUT_CD_CS_Pin POUT_C_Pin POUT_F_Pin POUT_EF_CS_Pin
                           POUT_E_Pin LCD_RST_Pin RTC_INT_Pin RTC_RST_Pin */
  GPIO_InitStruct.Pin = POUT_AB_CS_Pin|POUT_A_Pin|POUT_B_Pin|POUT_D_Pin
                          |POUT_CD_CS_Pin|POUT_C_Pin|POUT_F_Pin|POUT_EF_CS_Pin
                          |POUT_E_Pin|LCD_RST_Pin|RTC_INT_Pin|RTC_RST_Pin;
  GPIO_InitStruct.Mode = GPIO_MODE_OUTPUT_PP;
  GPIO_InitStruct.Pull = GPIO_NOPULL;
  GPIO_InitStruct.Speed = GPIO_SPEED_FREQ_LOW;
  HAL_GPIO_Init(GPIOE, &GPIO_InitStruct);

  /*Configure GPIO pin : BTN_Pin */
  GPIO_InitStruct.Pin = BTN_Pin;
  GPIO_InitStruct.Mode = GPIO_MODE_INPUT;
  GPIO_InitStruct.Pull = GPIO_NOPULL;
  HAL_GPIO_Init(BTN_GPIO_Port, &GPIO_InitStruct);

  /*Configure GPIO pins : ANALOG_SWITCH_Pin DIN_OFFSET_Pin */
  GPIO_InitStruct.Pin = ANALOG_SWITCH_Pin|DIN_OFFSET_Pin;
  GPIO_InitStruct.Mode = GPIO_MODE_OUTPUT_PP;
  GPIO_InitStruct.Pull = GPIO_NOPULL;
  GPIO_InitStruct.Speed = GPIO_SPEED_FREQ_LOW;
  HAL_GPIO_Init(GPIOF, &GPIO_InitStruct);

  /*Configure GPIO pins : CHARG_ON_Pin LED1_Pin LED2_Pin LED3_Pin
                           USB_ENB_Pin POUT_GH_CS_Pin POUT_G_Pin POUT_H_Pin
                           POUT_J_Pin */
  GPIO_InitStruct.Pin = CHARG_ON_Pin|LED1_Pin|LED2_Pin|LED3_Pin
                          |USB_ENB_Pin|POUT_GH_CS_Pin|POUT_G_Pin|POUT_H_Pin
                          |POUT_J_Pin;
  GPIO_InitStruct.Mode = GPIO_MODE_OUTPUT_PP;
  GPIO_InitStruct.Pull = GPIO_NOPULL;
  GPIO_InitStruct.Speed = GPIO_SPEED_FREQ_LOW;
  HAL_GPIO_Init(GPIOG, &GPIO_InitStruct);

  /*Configure GPIO pins : LCD_LED_Pin LCD_CS_Pin POUT_IJ_CS_Pin POUT_I_Pin */
  GPIO_InitStruct.Pin = LCD_LED_Pin|LCD_CS_Pin|POUT_IJ_CS_Pin|POUT_I_Pin;
  GPIO_InitStruct.Mode = GPIO_MODE_OUTPUT_PP;
  GPIO_InitStruct.Pull = GPIO_NOPULL;
  GPIO_InitStruct.Speed = GPIO_SPEED_FREQ_LOW;
  HAL_GPIO_Init(GPIOB, &GPIO_InitStruct);

  /*Configure GPIO pins : KL_UP_Pin KL_DOWN_Pin KL_START_Pin KL_AUTO_Pin
                           KL_STOP_Pin */
  GPIO_InitStruct.Pin = KL_UP_Pin|KL_DOWN_Pin|KL_START_Pin|KL_AUTO_Pin
                          |KL_STOP_Pin;
  GPIO_InitStruct.Mode = GPIO_MODE_INPUT;
  GPIO_InitStruct.Pull = GPIO_NOPULL;
  HAL_GPIO_Init(GPIOD, &GPIO_InitStruct);

  /*Configure GPIO pin : VR_COUNT_Pin */
  GPIO_InitStruct.Pin = VR_COUNT_Pin;
  GPIO_InitStruct.Mode = GPIO_MODE_IT_RISING;
  GPIO_InitStruct.Pull = GPIO_NOPULL;
  HAL_GPIO_Init(VR_COUNT_GPIO_Port, &GPIO_InitStruct);

  /*Configure GPIO pin : USB_DETECTED_Pin */
  GPIO_InitStruct.Pin = USB_DETECTED_Pin;
  GPIO_InitStruct.Mode = GPIO_MODE_INPUT;
  GPIO_InitStruct.Pull = GPIO_NOPULL;
  HAL_GPIO_Init(USB_DETECTED_GPIO_Port, &GPIO_InitStruct);

  /*Configure GPIO pin : SDIO_CD_Pin */
  GPIO_InitStruct.Pin = SDIO_CD_Pin;
  GPIO_InitStruct.Mode = GPIO_MODE_INPUT;
  GPIO_InitStruct.Pull = GPIO_NOPULL;
  HAL_GPIO_Init(SDIO_CD_GPIO_Port, &GPIO_InitStruct);

  /*Configure GPIO pin : EEPROM_NSS_Pin */
  GPIO_InitStruct.Pin = EEPROM_NSS_Pin;
  GPIO_InitStruct.Mode = GPIO_MODE_OUTPUT_PP;
  GPIO_InitStruct.Pull = GPIO_NOPULL;
  GPIO_InitStruct.Speed = GPIO_SPEED_FREQ_LOW;
  HAL_GPIO_Init(EEPROM_NSS_GPIO_Port, &GPIO_InitStruct);

  /*Configure GPIO pin : EEPROM_NSS_Pin */
  GPIO_InitStruct.Pin = MAC_NSS_Pin;
  GPIO_InitStruct.Mode = GPIO_MODE_OUTPUT_PP;
  GPIO_InitStruct.Pull = GPIO_NOPULL;
  GPIO_InitStruct.Speed = GPIO_SPEED_FREQ_LOW;
  HAL_GPIO_Init(MAC_NSS_GPIO_Port, &GPIO_InitStruct);

  /*Configure GPIO pins : PD0 PD1 */
  GPIO_InitStruct.Pin = GPIO_PIN_0|GPIO_PIN_1;
  GPIO_InitStruct.Mode = GPIO_MODE_AF_PP;
  GPIO_InitStruct.Pull = GPIO_NOPULL;
  GPIO_InitStruct.Speed = GPIO_SPEED_FREQ_VERY_HIGH;
  GPIO_InitStruct.Alternate = GPIO_AF9_CAN1;
  HAL_GPIO_Init(GPIOD, &GPIO_InitStruct);

  /*Configure GPIO pins : RS485_DE_Pin LED_SYS_Pin */
  GPIO_InitStruct.Pin = RS485_DE_Pin|LED_SYS_Pin;
  GPIO_InitStruct.Mode = GPIO_MODE_OUTPUT_PP;
  GPIO_InitStruct.Pull = GPIO_NOPULL;
  GPIO_InitStruct.Speed = GPIO_SPEED_FREQ_LOW;
  HAL_GPIO_Init(GPIOD, &GPIO_InitStruct);

  /* EXTI interrupt init*/
  HAL_NVIC_SetPriority(EXTI9_5_IRQn, 5, 0);
  HAL_NVIC_EnableIRQ(EXTI9_5_IRQn);

}

/* USER CODE BEGIN 4 */
const char startupMessage[25U] = "***********************\n";
/* USER CODE END 4 */

void StartDefaultTask(void *argument)
{
  /* init code for USB_DEVICE */
  MX_USB_DEVICE_Init();
  /* USER CODE BEGIN 5 */
  uint8_t period = 200U;
  vSERIALinit( &huart3 ); /* Debug serial interface */
  vDATAAPIinitMac( &macEE );
  HAL_GPIO_WritePin( LED_SYS_GPIO_Port, LED_SYS_Pin, GPIO_PIN_SET );
  vSERVERinit();
  if ( eSTORAGEinit( &storEE ) == EEPROM_OK )  /* EEPROM initialization */
  {
    if ( eDATAAPIdataInit() == EEPROM_OK ) /* Data from EEPROM initialization           */
    {
      if ( eDATAAPIlogInit() == EEPROM_OK ) /* Get log data from EEPROM                  */
      {
        HAL_GPIO_WritePin( DIN_OFFSET_GPIO_Port, DIN_OFFSET_Pin, GPIO_PIN_SET );
        vFATSDinit( &hsd );
        vSDinit();
        vCHARTupdateAtrib();                        /* Update charts attributes                  */
        while ( uADCGetValidDataFlag() == 0U )
        {
	        osDelay( 10U );
        }
        osDelay( 1100U );
        vVRinit( &htim6 );                          /* Speed sensor initialization        */
        vFPIinit( &fpiInitStruct );                 /* Free Program Input initialization  */
        vFPOinit( &fpoInitStruct );                 /* Free Program Output initialization */
        vCHARGERinit( &chargGPIO );                 /**/
        vALARMinit();                               /* Activ error list initialization    */
        HAL_GPIO_WritePin( USB_ENB_GPIO_Port, USB_ENB_Pin, GPIO_PIN_SET ); /* Enable USB, by pull-up to USB PD*/
        vENGINEinit();                              /**/
        vELECTROinit( &htim12 );                    /**/
        vLOGICinit( &htim5 );                       /**/
        vCONTROLLERinit( &controllerInitStruct );   /**/
        vOUTPUTinit();
        vMBinit( mbInit );                          /* Start ModBus                              */
        vMEASUREMENTinit();                         /**/
        period = 100U;
        #if defined ( UNIT_TEST )
          vTESTInit();
        #else
          vSYSserial( startupMessage, 24U );
        #endif
      }
    }
  }
  /* Infinite loop */
  for(;;)
  {
    HAL_GPIO_TogglePin( LED_SYS_GPIO_Port, LED_SYS_Pin );
    osDelay( period );
  }
  /* USER CODE END 5 */
}

void StartLcdTask(void *argument)
{
  /* USER CODE BEGIN StartLcdTask */
  vLCD_Init();
  for(;;)
  {
    vMenuTask();
  }
  /* USER CODE END StartLcdTask */
}

void vWDtask(void *argument)
{
  /* USER CODE BEGIN vWDtask */
  /* Infinite loop */
  for(;;)
  {
    HAL_IWDG_Refresh( &hiwdg );
    osDelay( 1500U );
  }
  /* USER CODE END vWDtask */
}

void HAL_TIM_PeriodElapsedCallback(TIM_HandleTypeDef *htim)
{
  if (htim->Instance == TIM4) {
    HAL_IncTick();
  }
}

void Error_Handler(void)
{
  __disable_irq();
  while (1)
  {
  }
}
